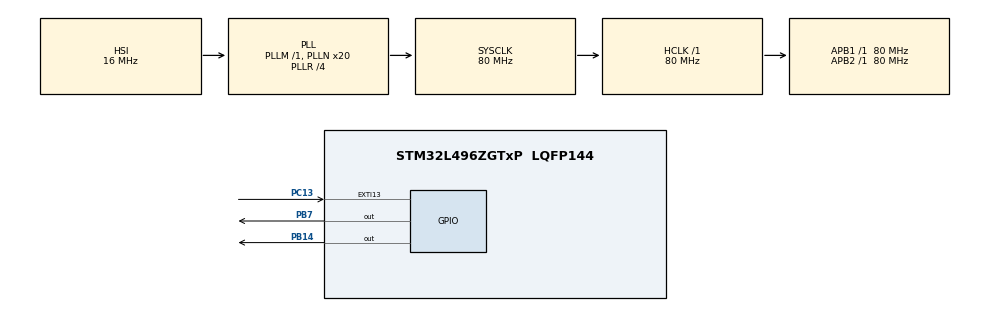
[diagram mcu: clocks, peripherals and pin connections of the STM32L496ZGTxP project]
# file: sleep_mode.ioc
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Mcu.Family=STM32L4
Mcu.Name=STM32L496ZGTxP
Mcu.Package=LQFP144
NVIC.PriorityGroup=NVIC_PRIORITYGROUP_4
PB14.Signal=GPIO_Output
PB7.Signal=GPIO_Output
PC13.Signal=GPXTI13
ProjectManager.HeapSize=0x200
ProjectManager.StackSize=0x400
ProjectManager.TargetToolchain=STM32CubeIDE
RCC.48MHZClocksFreq_Value=24000000
RCC.ADCFreq_Value=160000000
RCC.AHBFreq_Value=80000000
RCC.APB1Freq_Value=80000000
RCC.APB1TimFreq_Value=80000000
RCC.APB2Freq_Value=80000000
RCC.APB2TimFreq_Value=80000000
RCC.CortexFreq_Value=80000000
RCC.HCLKFreq_Value=80000000
RCC.HSE_VALUE=8000000
RCC.HSI48_VALUE=48000000
RCC.HSI_VALUE=16000000
RCC.LSE_VALUE=32768
RCC.MSI_VALUE=4000000
RCC.PLLMUL=RCC_PLL_MUL9
RCC.PLLN=20
RCC.PLLR=RCC_PLLR_DIV4
RCC.PLLSAI1N=20
RCC.PLLSourceVirtual=RCC_PLLSOURCE_HSI
RCC.PRESCALERUSB=RCC_USBCLKSOURCE_PLL_DIV1_5
RCC.SYSCLKFreq_VALUE=80000000
RCC.SYSCLKSource=RCC_SYSCLKSOURCE_PLLCLK
RCC.SYSCLKSourceVirtual=RCC_SYSCLKSOURCE_PLLCLK
RCC.USBFreq_Value=160000000
RCC.VCOOutputFreq_Value=320000000
board=NUCLEO-L496ZG-P

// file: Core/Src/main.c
#include "main.h"
#include "PWR_Driver.h"
void SystemClock_Config(void);
static void MX_GPIO_Init(void);
/* USER CODE BEGIN PFP */
//void PWR_EnterSleepMode(void);
void SystemClock_Config_Decrease(void);
/* USER CODE END PFP */

/* USER CODE BEGIN PV */
 volatile uint8_t sleepmode_activated=0;
 volatile uint8_t EntersleepFlag=0;
/* USER CODE END PV */

int main(void) {
	/* MCU Configuration--------------------------------------------------------*/

	/* Reset of all peripherals, Initializes the Flash interface and the Systick. */
	HAL_Init();
	/* Configure the system clock 80MHz*/
	SystemClock_Config();
	/* Initialize all configured peripherals */
	MX_GPIO_Init();
	/* USER CODE BEGIN 2 */
	FlashStateProfile();
	LP_System_Config();
	Peripheral_Sleep_Enable();
	disableTick();

	// State machine routine before going to sleep mode

	HAL_PWR_EnterSLEEPMode(PWR_LOWPOWERREGULATOR_ON, PWR_SLEEPENTRY_WFI);

	while (1) {
		/* USER CODE END WHILE */
		/* USER CODE BEGIN 3 */
		MX_GPIO_Init();
		HAL_GPIO_WritePin(GPIOB, GPIO_PIN_14, SET);
	}
	/* USER CODE END 3 */
}

void SystemClock_Config(void) {
	RCC_OscInitTypeDef RCC_OscInitStruct = { 0 };
	RCC_ClkInitTypeDef RCC_ClkInitStruct = { 0 };

	/** Configure the main internal regulator output voltage
	 */
	if (HAL_PWREx_ControlVoltageScaling(PWR_REGULATOR_VOLTAGE_SCALE1)
			!= HAL_OK) {
		Error_Handler();
	}

	/** Initializes the RCC Oscillators according to the specified parameters
	 * in the RCC_OscInitTypeDef structure.
	 */
	RCC_OscInitStruct.OscillatorType = RCC_OSCILLATORTYPE_HSI;
	RCC_OscInitStruct.HSIState = RCC_HSI_ON;
	RCC_OscInitStruct.HSICalibrationValue = RCC_HSICALIBRATION_DEFAULT;
	RCC_OscInitStruct.PLL.PLLState = RCC_PLL_ON;
	RCC_OscInitStruct.PLL.PLLSource = RCC_PLLSOURCE_HSI;
	RCC_OscInitStruct.PLL.PLLM = 1;
	RCC_OscInitStruct.PLL.PLLN = 20;
	RCC_OscInitStruct.PLL.PLLP = RCC_PLLP_DIV2;
	RCC_OscInitStruct.PLL.PLLQ = RCC_PLLQ_DIV2;
	RCC_OscInitStruct.PLL.PLLR = RCC_PLLR_DIV4;
	if (HAL_RCC_OscConfig(&RCC_OscInitStruct) != HAL_OK) {
		Error_Handler();
	}

	/** Initializes the CPU, AHB and APB buses clocks
	 */
	RCC_ClkInitStruct.ClockType = RCC_CLOCKTYPE_HCLK | RCC_CLOCKTYPE_SYSCLK
			| RCC_CLOCKTYPE_PCLK1 | RCC_CLOCKTYPE_PCLK2;
	RCC_ClkInitStruct.SYSCLKSource = RCC_SYSCLKSOURCE_PLLCLK;
	RCC_ClkInitStruct.AHBCLKDivider = RCC_SYSCLK_DIV1;
	RCC_ClkInitStruct.APB1CLKDivider = RCC_HCLK_DIV1;
	RCC_ClkInitStruct.APB2CLKDivider = RCC_HCLK_DIV1;

	if (HAL_RCC_ClockConfig(&RCC_ClkInitStruct, FLASH_LATENCY_4) != HAL_OK) {
		Error_Handler();
	}
}

static void MX_GPIO_Init(void) {
	GPIO_InitTypeDef GPIO_InitStruct = { 0 };

	/* GPIO Ports Clock Enable */
	__HAL_RCC_GPIOE_CLK_ENABLE();
	__HAL_RCC_GPIOC_CLK_ENABLE();
	__HAL_RCC_GPIOF_CLK_ENABLE();
	__HAL_RCC_GPIOH_CLK_ENABLE();
	__HAL_RCC_GPIOA_CLK_ENABLE();
	__HAL_RCC_GPIOB_CLK_ENABLE();
	__HAL_RCC_GPIOG_CLK_ENABLE();
	__HAL_RCC_GPIOD_CLK_ENABLE();
	HAL_PWREx_EnableVddIO2();

	/*Configure GPIO pin Output Level */
	HAL_GPIO_WritePin(GPIOB, GPIO_PIN_14 | GPIO_PIN_7, GPIO_PIN_RESET);

	/*Configure GPIO pins : PE2 PE3 PE4 PE5
	 PE6 PE7 PE8 PE9
	 PE10 PE11 PE12 PE13
	 PE14 PE15 PE0 PE1 */
	GPIO_InitStruct.Pin = GPIO_PIN_2 | GPIO_PIN_3 | GPIO_PIN_4 | GPIO_PIN_5
			| GPIO_PIN_6 | GPIO_PIN_7 | GPIO_PIN_8 | GPIO_PIN_9 | GPIO_PIN_10
			| GPIO_PIN_11 | GPIO_PIN_12 | GPIO_PIN_13 | GPIO_PIN_14
			| GPIO_PIN_15 | GPIO_PIN_0 | GPIO_PIN_1;
	GPIO_InitStruct.Mode = GPIO_MODE_ANALOG;
	GPIO_InitStruct.Pull = GPIO_NOPULL;
	HAL_GPIO_Init(GPIOE, &GPIO_InitStruct);

	/*Configure GPIO pin : PC13 */
	GPIO_InitStruct.Pin = GPIO_PIN_13;
	GPIO_InitStruct.Mode = GPIO_MODE_IT_RISING;
	GPIO_InitStruct.Pull = GPIO_NOPULL;
	HAL_GPIO_Init(GPIOC, &GPIO_InitStruct);

	/*Configure GPIO pins : PC14 PC15 PC0 PC1
	 PC2 PC3 PC4 PC5
	 PC6 PC7 PC8 PC9
	 PC10 PC11 PC12 */
	GPIO_InitStruct.Pin = GPIO_PIN_14 | GPIO_PIN_15 | GPIO_PIN_0 | GPIO_PIN_1
			| GPIO_PIN_2 | GPIO_PIN_3 | GPIO_PIN_4 | GPIO_PIN_5 | GPIO_PIN_6
			| GPIO_PIN_7 | GPIO_PIN_8 | GPIO_PIN_9 | GPIO_PIN_10 | GPIO_PIN_11
			| GPIO_PIN_12;
	GPIO_InitStruct.Mode = GPIO_MODE_ANALOG;
	GPIO_InitStruct.Pull = GPIO_NOPULL;
	HAL_GPIO_Init(GPIOC, &GPIO_InitStruct);

	/*Configure GPIO pins : PF0 PF1 PF2 PF3
	 PF4 PF5 PF6 PF7
	 PF8 PF9 PF10 PF11
	 PF12 PF13 PF14 PF15 */
	GPIO_InitStruct.Pin = GPIO_PIN_0 | GPIO_PIN_1 | GPIO_PIN_2 | GPIO_PIN_3
			| GPIO_PIN_4 | GPIO_PIN_5 | GPIO_PIN_6 | GPIO_PIN_7 | GPIO_PIN_8
			| GPIO_PIN_9 | GPIO_PIN_10 | GPIO_PIN_11 | GPIO_PIN_12 | GPIO_PIN_13
			| GPIO_PIN_14 | GPIO_PIN_15;
	GPIO_InitStruct.Mode = GPIO_MODE_ANALOG;
	GPIO_InitStruct.Pull = GPIO_NOPULL;
	HAL_GPIO_Init(GPIOF, &GPIO_InitStruct);

	/*Configure GPIO pins : PH0 PH1 PH3 */
	GPIO_InitStruct.Pin = GPIO_PIN_0 | GPIO_PIN_1 | GPIO_PIN_3;
	GPIO_InitStruct.Mode = GPIO_MODE_ANALOG;
	GPIO_InitStruct.Pull = GPIO_NOPULL;
	HAL_GPIO_Init(GPIOH, &GPIO_InitStruct);

	/*Configure GPIO pins : PA0 PA1 PA2 PA3
	 PA4 PA5 PA6 PA7
	 PA8 PA9 PA10 PA11
	 PA12 PA13 PA14 PA15 */
	GPIO_InitStruct.Pin = GPIO_PIN_0 | GPIO_PIN_1 | GPIO_PIN_2 | GPIO_PIN_3
			| GPIO_PIN_4 | GPIO_PIN_5 | GPIO_PIN_6 | GPIO_PIN_7 | GPIO_PIN_8
			| GPIO_PIN_9 | GPIO_PIN_10 | GPIO_PIN_11 | GPIO_PIN_12 | GPIO_PIN_13
			| GPIO_PIN_14 | GPIO_PIN_15;
	GPIO_InitStruct.Mode = GPIO_MODE_ANALOG;
	GPIO_InitStruct.Pull = GPIO_NOPULL;
	// HAL_GPIO_Init(GPIOA, &GPIO_InitStruct);

	/*Configure GPIO pins : PB0 PB1 PB2 PB10
	 PB12 PB13 PB15 PB3
	 PB4 PB5 PB6 PB8
	 PB9 */
	GPIO_InitStruct.Pin = GPIO_PIN_0 | GPIO_PIN_1 | GPIO_PIN_2 | GPIO_PIN_10
			| GPIO_PIN_12 | GPIO_PIN_13 | GPIO_PIN_15 | GPIO_PIN_3 | GPIO_PIN_4
			| GPIO_PIN_5 | GPIO_PIN_6 | GPIO_PIN_8 | GPIO_PIN_9;
	GPIO_InitStruct.Mode = GPIO_MODE_ANALOG;
	GPIO_InitStruct.Pull = GPIO_NOPULL;
	HAL_GPIO_Init(GPIOB, &GPIO_InitStruct);

	/*Configure GPIO pins : PG0 PG1 PG2 PG3
	 PG4 PG5 PG6 PG7
	 PG8 PG9 PG10 PG11
	 PG12 PG13 PG14 */
	GPIO_InitStruct.Pin = GPIO_PIN_0 | GPIO_PIN_1 | GPIO_PIN_2 | GPIO_PIN_3
			| GPIO_PIN_4 | GPIO_PIN_5 | GPIO_PIN_6 | GPIO_PIN_7 | GPIO_PIN_8
			| GPIO_PIN_9 | GPIO_PIN_10 | GPIO_PIN_11 | GPIO_PIN_12 | GPIO_PIN_13
			| GPIO_PIN_14;
	GPIO_InitStruct.Mode = GPIO_MODE_ANALOG;
	GPIO_InitStruct.Pull = GPIO_NOPULL;
	HAL_GPIO_Init(GPIOG, &GPIO_InitStruct);

	/*Configure GPIO pins : PB14 PB7 */
	GPIO_InitStruct.Pin = GPIO_PIN_14 | GPIO_PIN_7;
	GPIO_InitStruct.Mode = GPIO_MODE_OUTPUT_PP;
	GPIO_InitStruct.Pull = GPIO_NOPULL;
	GPIO_InitStruct.Speed = GPIO_SPEED_FREQ_LOW;
	HAL_GPIO_Init(GPIOB, &GPIO_InitStruct);

	/*Configure GPIO pins : PD8 PD9 PD10 PD11
	 PD12 PD13 PD14 PD15
	 PD0 PD1 PD2 PD3
	 PD4 PD5 PD6 PD7 */
	GPIO_InitStruct.Pin = GPIO_PIN_8 | GPIO_PIN_9 | GPIO_PIN_10 | GPIO_PIN_11
			| GPIO_PIN_12 | GPIO_PIN_13 | GPIO_PIN_14 | GPIO_PIN_15 | GPIO_PIN_0
			| GPIO_PIN_1 | GPIO_PIN_2 | GPIO_PIN_3 | GPIO_PIN_4 | GPIO_PIN_5
			| GPIO_PIN_6 | GPIO_PIN_7;
	GPIO_InitStruct.Mode = GPIO_MODE_ANALOG;
	GPIO_InitStruct.Pull = GPIO_NOPULL;
	HAL_GPIO_Init(GPIOD, &GPIO_InitStruct);

	/* EXTI interrupt init (making thhe push button's priority as higher one to execute even at sleep mode)*/
	HAL_NVIC_SetPriority(EXTI15_10_IRQn, 0, 0);
	HAL_NVIC_EnableIRQ(EXTI15_10_IRQn);

}

/* USER CODE BEGIN 4 */

/*void PWR_EnterSleepMode(void)
 {
 HAL_SuspendTick();
 HAL_PWR_EnterSLEEPMode(PWR_LOWPOWERREGULATOR_ON,PWR_SLEEPENTRY_WFI);
 HAL_ResumeTick();
 }*/

//void PWR_EnterStopMode(void)
//{
//	HAL_SuspendTick();
//	HAL_PWREx_EnterSTOP0Mode(PWR_STOPENTRY_WFI);
//	HAL_ResumeTick();
//}
//void HAL_GPIO_EXTI_Callback(uint16_t GPIO_Pin)
//{
//	if(GPIO_Pin==GPIO_PIN_13)
//	{
//		HAL_GPIO_TogglePin(GPIOB,GPIO_PIN_14);
//	   // HAL_Delay(150);
//	}
//}
void HAL_GPIO_EXTI_Callback(uint16_t GPIO_Pin) {
	if (GPIO_Pin == GPIO_PIN_13) {
		if (sleepmode_activated == 1) {
			HAL_PWREx_DisableLowPowerRunMode();
			__HAL_RCC_PWR_CLK_DISABLE();

			HAL_ResumeTick();
			__enable_irq();
			__HAL_RCC_HSI_ENABLE();
			SystemClock_Config();
			sleepmode_activated = 0;
		} else {
			// Re-Enter Sleep Mode!
			EntersleepFlag = 1;
		}
	}
}

void SystemClock_Config_Decrease(void) {
	RCC_ClkInitTypeDef RCC_ClkInitStruct = { 0 };
	RCC_OscInitTypeDef RCC_OscInitStruct = { 0 };

	/* Select MSI as system clock source */
	RCC_ClkInitStruct.ClockType = RCC_CLOCKTYPE_SYSCLK;
	RCC_ClkInitStruct.SYSCLKSource = RCC_SYSCLKSOURCE_MSI;
	if (HAL_RCC_ClockConfig(&RCC_ClkInitStruct, FLASH_LATENCY_0) != HAL_OK) //0 Wait states for 2Mhz frequency
			{
		/* Initialization Error */
		Error_Handler();
	}

	/* Update MSI to 24Mhz (RCC_MSIRANGE_9) */
	RCC_OscInitStruct.OscillatorType = RCC_OSCILLATORTYPE_MSI;
	RCC_OscInitStruct.MSIState = RCC_MSI_ON;
	RCC_OscInitStruct.MSIClockRange = RCC_MSIRANGE_0;                   //100KHz
	RCC_OscInitStruct.MSICalibrationValue = RCC_MSICALIBRATION_DEFAULT;
	RCC_OscInitStruct.PLL.PLLState = RCC_PLL_OFF;
	if (HAL_RCC_OscConfig(&RCC_OscInitStruct) != HAL_OK) {
		/* Initialization Error */
		Error_Handler();
	}
	__HAL_RCC_HSI_DISABLE();
}

/* USER CODE END 4 */

void Error_Handler(void) {
	__disable_irq();
	while (1) {
	}
}
